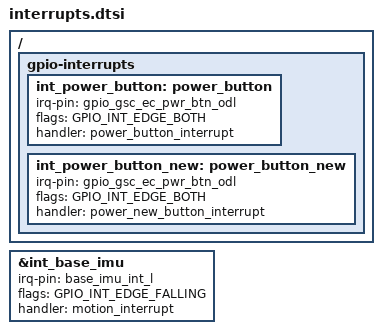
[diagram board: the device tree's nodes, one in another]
/* Copyright 2022 The ChromiumOS Authors
 * Use of this source code is governed by a BSD-style license that can be
 * found in the LICENSE file.
 */

 /* This file should only be included in the project.overlay. */
&int_base_imu {
	irq-pin = <&base_imu_int_l>;
	flags = <GPIO_INT_EDGE_FALLING>;
	handler = "motion_interrupt";
};
/{
	gpio-interrupts {
		int_power_button: power_button {
			irq-pin = <&gpio_gsc_ec_pwr_btn_odl>;
			flags = <GPIO_INT_EDGE_BOTH>;
			handler = "power_button_interrupt";
		};
		
		int_power_button_new: power_button_new {
			irq-pin = <&gpio_gsc_ec_pwr_btn_odl>;
			flags = <GPIO_INT_EDGE_BOTH>;
			handler = "power_new_button_interrupt";
		};
	};
};
